VERSION ""

NS_ :

BS_:

BU_: SCLX MABX

BO_ 1 STEERING_CMD: 2 MABX
 SG_ STEERING_ANGLE_CMD : 0|16@1- (0.0004,0) [-13.1072|13.1068] "rad"  SCLX

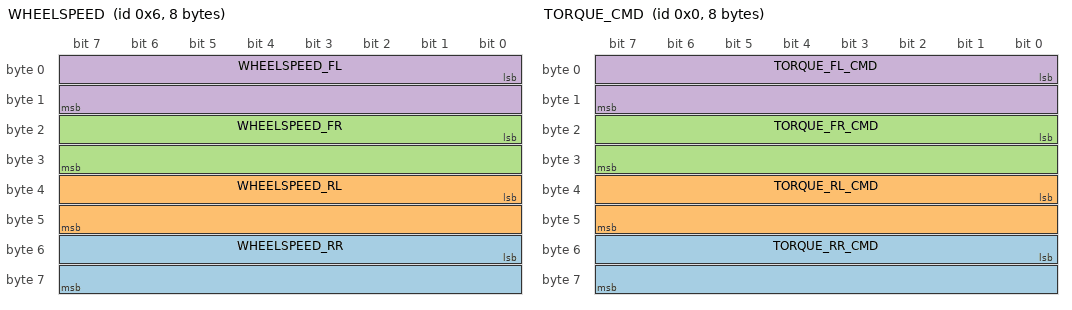
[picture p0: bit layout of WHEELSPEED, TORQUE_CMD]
BO_ 6 WHEELSPEED: 8 SCLX
 SG_ WHEELSPEED_RR : 48|16@1- (0.006,0) [-196.608|196.602] "rad/s"  MABX
 SG_ WHEELSPEED_RL : 32|16@1- (0.006,0) [-196.608|196.602] "rad/s"  MABX
 SG_ WHEELSPEED_FR : 16|16@1- (0.006,0) [-196.608|196.602] "rad/s"  MABX
 SG_ WHEELSPEED_FL : 0|16@1- (0.006,0) [-196.608|196.602] "rad/s"  MABX

BO_ 0 TORQUE_CMD: 8 MABX
 SG_ TORQUE_RR_CMD : 48|16@1- (0.075,0) [-2457.6|2457.525] "Nm"  SCLX
 SG_ TORQUE_RL_CMD : 32|16@1- (0.075,0) [-2457.6|2457.525] "Nm"  SCLX
 SG_ TORQUE_FR_CMD : 16|16@1- (0.075,0) [-2457.6|2457.525] "Nm"  SCLX
 SG_ TORQUE_FL_CMD : 0|16@1- (0.075,0) [-2457.6|2457.525] "Nm"  SCLX

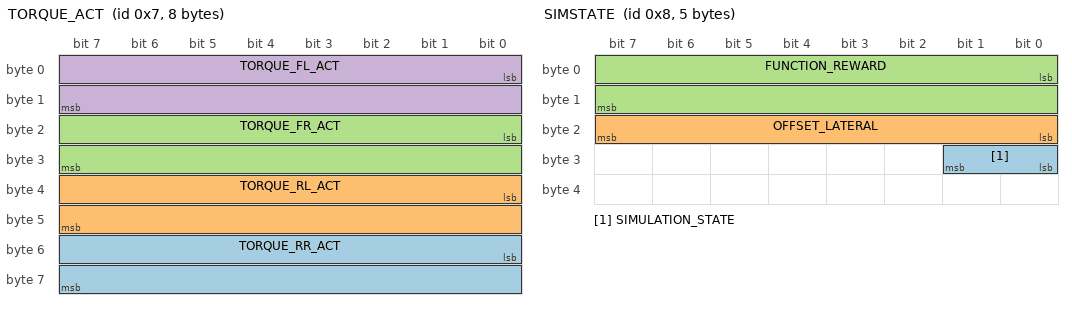
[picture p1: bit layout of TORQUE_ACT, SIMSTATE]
BO_ 7 TORQUE_ACT: 8 SCLX
 SG_ TORQUE_RR_ACT : 48|16@1- (0.075,0) [-2457.6|2457.525] "Nm"  MABX
 SG_ TORQUE_RL_ACT : 32|16@1- (0.075,0) [-2457.6|2457.525] "Nm"  MABX
 SG_ TORQUE_FR_ACT : 16|16@1- (0.075,0) [-2457.6|2457.525] "Nm"  MABX
 SG_ TORQUE_FL_ACT : 0|16@1- (0.075,0) [-2457.6|2457.525] "Nm"  MABX

BO_ 8 SIMSTATE: 5 SCLX
 SG_ SIMULATION_STATE : 24|2@1- (1,0) [0|4] ""  MABX
 SG_ OFFSET_LATERAL : 16|8@1- (0.05,0) [-6.4|6.35] "m"  MABX
 SG_ FUNCTION_REWARD : 0|16@1+ (0.015,0) [0|983.025] ""  MABX

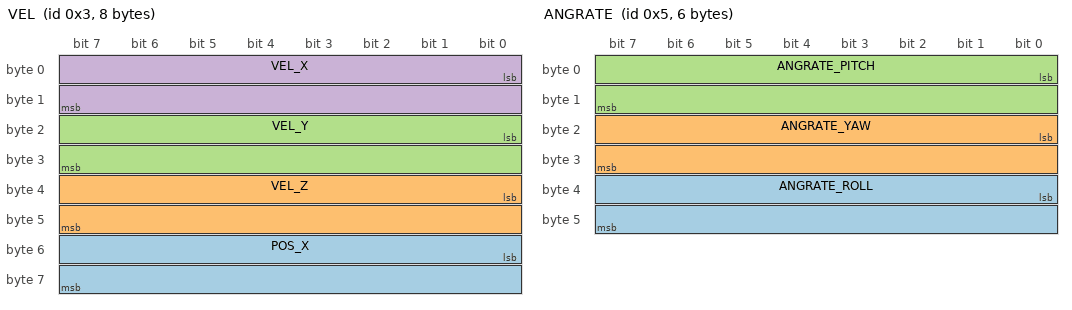
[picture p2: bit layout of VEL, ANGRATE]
BO_ 3 VEL: 8 SCLX
 SG_ POS_X : 48|16@1- (0.005,0) [-163.84|163.835] "m"  MABX
 SG_ VEL_Z : 32|16@1- (0.002,0) [-65.536|65.534] "m/s"  MABX
 SG_ VEL_Y : 16|16@1- (0.002,0) [-65.536|65.534] "m/s"  MABX
 SG_ VEL_X : 0|16@1- (0.002,0) [-65.536|65.534] "m/s"  MABX

BO_ 5 ANGRATE: 6 SCLX
 SG_ ANGRATE_ROLL : 32|16@1- (0.001,0) [-32.768|32.767] "rad/s"  MABX
 SG_ ANGRATE_YAW : 16|16@1- (0.001,0) [-32.768|32.767] "rad/s"  MABX
 SG_ ANGRATE_PITCH : 0|16@1- (0.001,0) [-32.768|32.767] "rad/s"  MABX

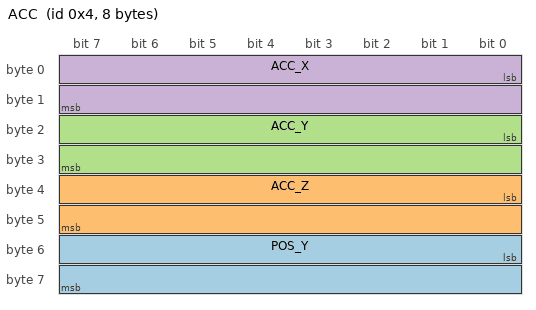
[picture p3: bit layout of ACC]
BO_ 4 ACC: 8 SCLX
 SG_ POS_Y : 48|16@1- (0.005,0) [-163.84|163.835] "m"  MABX
 SG_ ACC_Z : 32|16@1- (0.0006,0) [-19.6608|19.6602] "m/s^2"  MABX
 SG_ ACC_Y : 16|16@1- (0.0006,0) [-19.6608|19.6602] "m/s^2"  MABX
 SG_ ACC_X : 0|16@1- (0.0006,0) [-19.6608|19.6602] "m/s^2"  MABX
